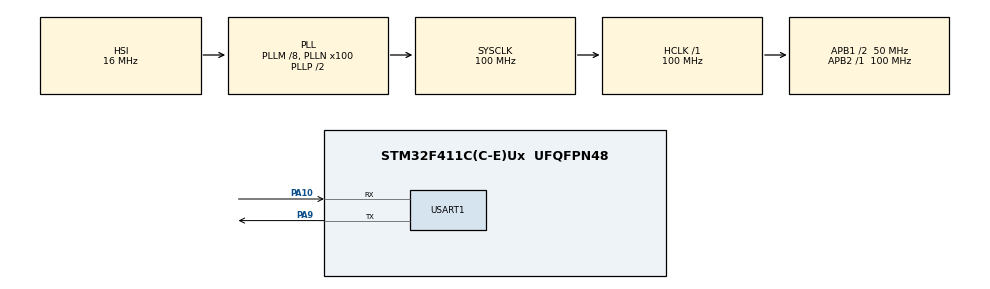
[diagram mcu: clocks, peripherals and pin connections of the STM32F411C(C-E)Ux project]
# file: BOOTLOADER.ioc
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Mcu.Family=STM32F4
Mcu.Name=STM32F411C(C-E)Ux
Mcu.Package=UFQFPN48
NVIC.PriorityGroup=NVIC_PRIORITYGROUP_4
NVIC.TIM1_UP_TIM10_IRQn=true\:15\:0\:false\:false\:true\:false\:true\:true
NVIC.TimeBase=TIM1_UP_TIM10_IRQn
NVIC.TimeBaseIP=TIM1
PA10.Mode=Asynchronous
PA10.Signal=USART1_RX
PA13.Mode=Serial_Wire
PA13.Signal=SYS_JTMS-SWDIO
PA14.Mode=Serial_Wire
PA14.Signal=SYS_JTCK-SWCLK
PA9.Mode=Asynchronous
PA9.Signal=USART1_TX
PC14-OSC32_IN.Mode=LSE-External-Oscillator
PC14-OSC32_IN.Signal=RCC_OSC32_IN
PC15-OSC32_OUT.Mode=LSE-External-Oscillator
PC15-OSC32_OUT.Signal=RCC_OSC32_OUT
PH0\ -\ OSC_IN.Mode=HSE-External-Oscillator
PH0\ -\ OSC_IN.Signal=RCC_OSC_IN
PH1\ -\ OSC_OUT.Mode=HSE-External-Oscillator
PH1\ -\ OSC_OUT.Signal=RCC_OSC_OUT
ProjectManager.HeapSize=0x200
ProjectManager.StackSize=0x400
ProjectManager.TargetToolchain=MDK-ARM V5.32
RCC.48MHZClocksFreq_Value=50000000
RCC.AHBFreq_Value=100000000
RCC.APB1CLKDivider=RCC_HCLK_DIV2
RCC.APB1Freq_Value=50000000
RCC.APB1TimFreq_Value=100000000
RCC.APB2Freq_Value=100000000
RCC.APB2TimFreq_Value=100000000
RCC.CortexFreq_Value=100000000
RCC.HCLKFreq_Value=100000000
RCC.HSE_VALUE=25000000
RCC.HSI_VALUE=16000000
RCC.PLLM=8
RCC.PLLN=100
RCC.SYSCLKFreq_VALUE=100000000
RCC.SYSCLKSource=RCC_SYSCLKSOURCE_PLLCLK
RCC.VCOOutputFreq_Value=200000000
USART1.VirtualMode=VM_ASYNC
VP_SYS_VS_tim1.Mode=TIM1
board=custom

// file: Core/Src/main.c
/* USER CODE BEGIN Header */
/**
  ******************************************************************************
  * @file           : main.c
  * @brief          : Main program body
  ******************************************************************************
  * @attention
  *
  * Copyright (c) 2026 STMicroelectronics.
  * All rights reserved.
  *
  * This software is licensed under terms that can be found in the LICENSE file
  * in the root directory of this software component.
  * If no LICENSE file comes with this software, it is provided AS-IS.
  *
  ******************************************************************************
  */
/* USER CODE END Header */
#include "main.h"
#include "usart.h"
#include "gpio.h"

/* USER CODE BEGIN PTD */
#define FALSH_BASE_ADDR 0x08000000//+ 0x00019000
#define APP_FLASH_ADDR 0x08008000 //APP程序的启动地址-MSP
typedef void (*pFunc)(void);      //pFunc 是变量名'，类型是 void (*)(void)。
pFunc Jump2Application;//函数指针类型--变量
                        //完全等价与 void (*Jump2Application)(void)
uint32_t JumpAddress;
 void delay(volatile uint32_t count)
{
	while(count--)
	{
		//延时1个时钟周期
		//空操作
	}
}
void delay_seconds(uint32_t seconds)
{
	uint32_t count = 100000000;
	for(uint32_t i = 0;i < seconds;i++)
	{
		delay(count);//ַԃғʱ
	}
}
/* USER CODE END PTD */

/* USER CODE BEGIN PD */
/*define func pointer*/
/**关闭外设函数 */
void DisablePeriphClock_irq(void){
/**  //串口关闭
  // HAL_UART_DeInit(&huart1);
  //关闭所有外设时钟/
  __HAL_RCC_RTC_DISABLE();
  ///中断禁用
  __disable_irq(); */
    HAL_DeInit();
    HAL_RCC_DeInit();
    // 关闭所有中断---防止加了rtos出问题
    __set_PRIMASK(1);
      // 2. 彻底关闭 SysTick 并且清除所有NVIC中断（极其关键！）
    SysTick->CTRL = 0;
    SysTick->LOAD = 0;
    SysTick->VAL = 0;
    for (int i = 0; i < 8; i++) {
        NVIC->ICER[i] = 0xFFFFFFFF; // 关闭全部中断
        NVIC->ICPR[i] = 0xFFFFFFFF; // 清除所有挂起的中断
    }
}
/**跳转函数 */
void Jump2App(void){
//  uint32_t jumpAddr,,i;
	uint32_t armAddr;

	armAddr = *(__IO uint32_t*)APP_FLASH_ADDR; //读取app程序的初始堆栈地址
	printf("app stack :0x%08X\r\n",armAddr);
uint32_t mspAddr;mspAddr = *(__IO uint32_t*)FALSH_BASE_ADDR;
	printf("msp :0x%08X\r\n",mspAddr);
  if(((*(__IO uint32_t*)APP_FLASH_ADDR) & 0x2FFE0000) == 0x20000000){ //判断地址是否合法//0x2FFE0000
    printf("jump addr start\r\n");
 	DisablePeriphClock_irq();
      /**取出app加载地址0x00019000-》将数字转成指针（地址）-》
       * 将falsh中的地址解引用查到地址中的存好的值-》判断这个值是否是RAM地址-128kb
       * */
    // 1. 从Flash读取应用程序的复位向量地址（PC指针）----这里是ram地址????
    JumpAddress = *(__IO uint32_t*)(APP_FLASH_ADDR + 4);
//    printf("jump addr :0x%08X\r\n",JumpAddress);

    // 2. 把地址转成函数指针类型，赋值给变量
    Jump2Application = (pFunc)JumpAddress;//类型是 void (*)(void)
    // 3. 设置主堆栈指针（MSP）为应用程序的初始堆栈地址
    __set_MSP(*(__IO uint32_t*)APP_FLASH_ADDR);/////////将栈顶指针手动设置
    // 4. 跳转到应用程序的复位向量地址，开始执行应用程序
    Jump2Application();

  }else{
    printf("jump app addr error\r\n");
  }
}

/* USER CODE END PD */

/* USER CODE END PD */

void SystemClock_Config(void);

int main(void)
{

  /* USER CODE BEGIN 1 */
  SCB->VTOR = 0x08000000 | 0x0; //设置向量表偏移地址为0x08000000
  /* USER CODE END 1 */

  /* MCU Configuration--------------------------------------------------------*/

  /* Reset of all peripherals, Initializes the Flash interface and the Systick. */
  HAL_Init();

  /* Configure the system clock */
  SystemClock_Config();
  // SystemInit();////////////////////////

  /* Initialize all configured peripherals */
  MX_GPIO_Init();
  MX_USART1_UART_Init();
  printf("start bootloader main running\r\n");
   /* USER CODE BEGIN 2 */
   Jump2App();

  /* USER CODE END 2 */
  /* Infinite loop */
  while (1)
  {

  }
}

void SystemClock_Config(void)
{
  RCC_OscInitTypeDef RCC_OscInitStruct = {0};
  RCC_ClkInitTypeDef RCC_ClkInitStruct = {0};

  /** Configure the main internal regulator output voltage
  */
  __HAL_RCC_PWR_CLK_ENABLE();
  __HAL_PWR_VOLTAGESCALING_CONFIG(PWR_REGULATOR_VOLTAGE_SCALE1);

  /** Initializes the RCC Oscillators according to the specified parameters
  * in the RCC_OscInitTypeDef structure.
  */
  RCC_OscInitStruct.OscillatorType = RCC_OSCILLATORTYPE_HSI;
  RCC_OscInitStruct.HSIState = RCC_HSI_ON;
  RCC_OscInitStruct.HSICalibrationValue = RCC_HSICALIBRATION_DEFAULT;
  RCC_OscInitStruct.PLL.PLLState = RCC_PLL_ON;
  RCC_OscInitStruct.PLL.PLLSource = RCC_PLLSOURCE_HSI;
  RCC_OscInitStruct.PLL.PLLM = 8;
  RCC_OscInitStruct.PLL.PLLN = 100;
  RCC_OscInitStruct.PLL.PLLP = RCC_PLLP_DIV2;
  RCC_OscInitStruct.PLL.PLLQ = 4;
  if (HAL_RCC_OscConfig(&RCC_OscInitStruct) != HAL_OK)
  {
    Error_Handler();
  }

  /** Initializes the CPU, AHB and APB buses clocks
  */
  RCC_ClkInitStruct.ClockType = RCC_CLOCKTYPE_HCLK|RCC_CLOCKTYPE_SYSCLK
                              |RCC_CLOCKTYPE_PCLK1|RCC_CLOCKTYPE_PCLK2;
  RCC_ClkInitStruct.SYSCLKSource = RCC_SYSCLKSOURCE_PLLCLK;
  RCC_ClkInitStruct.AHBCLKDivider = RCC_SYSCLK_DIV1;
  RCC_ClkInitStruct.APB1CLKDivider = RCC_HCLK_DIV2;
  RCC_ClkInitStruct.APB2CLKDivider = RCC_HCLK_DIV1;

  if (HAL_RCC_ClockConfig(&RCC_ClkInitStruct, FLASH_LATENCY_3) != HAL_OK)
  {
    Error_Handler();
  }
}

void HAL_TIM_PeriodElapsedCallback(TIM_HandleTypeDef *htim)
{
  if (htim->Instance == TIM1) {
    HAL_IncTick();
  }
}

void Error_Handler(void)
{
  __disable_irq();
  while (1)
  {
  }
}
